# STM32U385 register map
File version: 1.0
CPU: CM33 r0p1, little endian, MPU, FPU, 4 interrupt priority bits
Registers are 32-bit, read-write, reset 0x0 unless marked. A register's access mark holds for its fields unless they carry their own. Offsets are from the block's base; [hi:lo] are bit positions; {n}, {i} and the like mark numbered series.

## DLYBSD1 — DLYB Address block
Base 0x420C8400
Same registers: DLYBOS1 0x420CF000, SEC_DLYBSD1 0x520C8400, SEC_DLYBOS1 0x520CF000
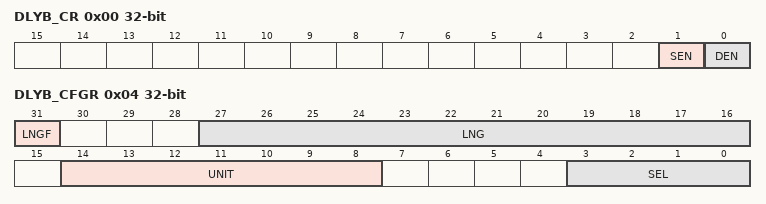
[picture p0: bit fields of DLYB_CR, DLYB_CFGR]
0x00 DLYB_CR — DLYB control register
  [1] SEN — 0: Sampler length and register access to UNIT[6:0] and SEL[3:0] disabled, output clock enabled. 1: Sampler length and register access to UNIT[6:0] and SEL[3:0] enabled, output clock disabled.
    0=Sampler length and register access to UNIT[6:0] and SEL[3:0] disabled, output clock enabled; 1=Sampler length and register access to UNIT[6:0] and SEL[3:0] enabled, output clock disabled
  [0] DEN — 0: DLYB disabled. 1: DLYB enabled.
    0=DLYB disabled; 1=DLYB enabled
0x04 DLYB_CFGR access per field — DLYB configuration register
  [31] LNGF ro — This flag indicates when the delay line length value contained in LNG[11:0] is valid after UNIT[6:0] bits changed. 0: Length value in LNG is not valid. 1: Length value in LNG is valid.
    0=Length value in LNG is not valid; 1=Length value in LNG is valid
  [27:16] LNG ro — These bits reflect the 12 unit delay values sampled at the rising edge of the input clock. The value is only valid when LNGF = 1.
  [14:8] UNIT rw — These bits can only be written when SEN = 1. Unit delay = initial delay + UNIT[6:0] x delay step
  [3:0] SEL rw — These bits can only be written when SEN = 1. Output clock phase = input clock + SEL[3:0] x unit delay

## ExTI — ExTI address block description
Base 0x40032000
Same registers: SEC_ExTI 0x50032000
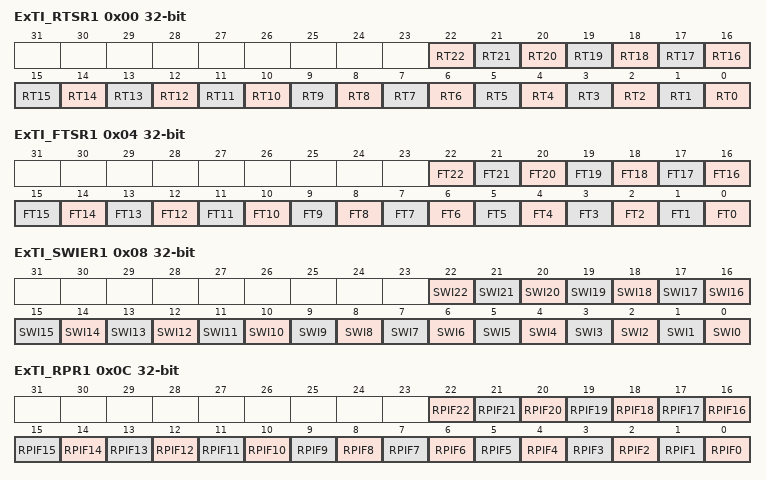
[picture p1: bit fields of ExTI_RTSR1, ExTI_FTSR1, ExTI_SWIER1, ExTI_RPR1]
0x00 ExTI_RTSR1 — ExTI rising trigger selection register
  [all] fields
    0=Rising trigger disabled (for event and interrupt) for input line; 1=Rising trigger enabled (for event and interrupt) for input line
  [n] RT{n} (n=0..22) — Rising trigger event configuration bit of configurable event input i
0x04 ExTI_FTSR1 — ExTI falling trigger selection register
  [all] fields
    0=Falling trigger disabled (for event and interrupt) for input line; 1=Falling trigger enabled (for event and interrupt) for input line
  [n] FT{n} (n=0..22) — Falling trigger event configuration bit of configurable event input i
0x08 ExTI_SWIER1 — ExTI software interrupt event register
  [all] fields
    0=Writing 0 has no effect; 1=Writing 1 triggers a rising edge event on event i
  [n] SWI{n} (n=0..22) — Software interrupt on event i
0x0C ExTI_RPR1 — ExTI rising edge pending register
  [all] fields
    0=No rising edge trigger request occurred; 1=Rising edge trigger request occurred
  [n] RPIF{n} (n=0..22) — Configurable event input i rising edge pending bit
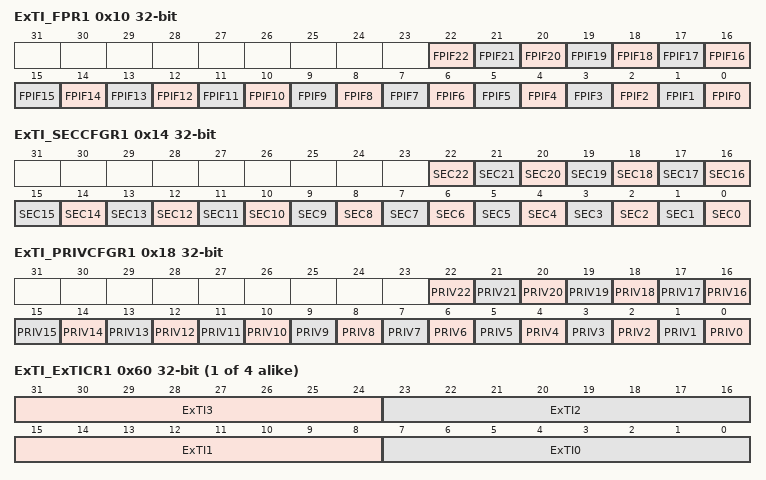
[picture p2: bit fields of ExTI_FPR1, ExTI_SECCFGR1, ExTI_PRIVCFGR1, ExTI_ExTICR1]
0x10 ExTI_FPR1 — ExTI falling edge pending register
  [all] fields
    0=No falling edge trigger request occurred; 1=Falling edge trigger request occurred
  [n] FPIF{n} (n=0..22) — configurable event inputs i falling edge pending bit
0x14 ExTI_SECCFGR1 — ExTI security configuration register
  [all] fields
    0=Event security disabled (nonsecure); 1=Event security enabled (secure)
  [n] SEC{n} (n=0..22) — Security enable on event input i
0x18 ExTI_PRIVCFGR1 — ExTI privilege configuration register
  [all] fields
    0=Event privilege disabled (unprivileged); 1=Event privilege enabled (privileged)
  [n] PRIV{n} (n=0..22) — Security enable on event input i
{0x5C+4i} ExTI_ExTICR{i} (i=1..4) — ExTI external interrupt selection register
  [31:24] ExTI{4i-1} — ExTI{4i-1} GPIO port selection
    0=PA[{4i-1}] pin; 1=PB[{4i-1}] pin; 2=PC[{4i-1}] pin; 3=PD[{4i-1}] pin; 4=PE[{4i-1}] pin; 6=PG[{4i-1}] pin; 7=PH[{4i-1}] pin
  [23:16] ExTI{4i-2} — ExTI{4i-2} GPIO port selection
    0=PA[{4i-2}] pin; 1=PB[{4i-2}] pin; 2=PC[{4i-2}] pin; 3=PD[{4i-2}] pin; 4=PE[{4i-2}] pin; 6=PG[{4i-2}] pin; 7=PH[{4i-2}] pin
  [15:8] ExTI{4i-3}
  [7:0] ExTI{4i-4}
0x70 ExTI_LOCKR — ExTI lock register
  [0] LOCK — Global security and privilege configuration registers (ExTI_SECCFGR and ExTI_PRIVCFGR) lock
    0=Security and privilege configuration open, can be modified; 1=Security and privilege configuration locked, can no longer be modified
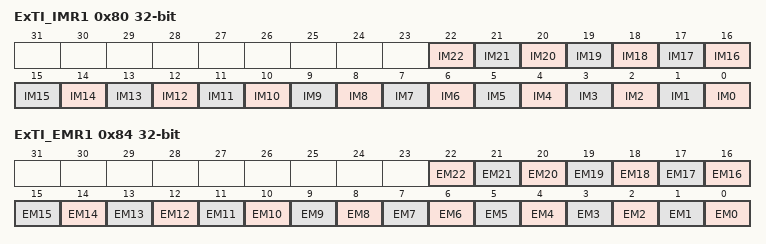
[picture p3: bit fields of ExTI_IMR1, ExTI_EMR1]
0x80 ExTI_IMR1 — ExTI CPU wake-up with interrupt mask register
  [all] fields
    0=Wake-up with interrupt request from input event i is masked; 1=Wake-up with interrupt request from input event i is unmasked
  [n] IM{n} (n=0..22) — CPU wake-up with interrupt mask on event input i
0x84 ExTI_EMR1 — ExTI CPU wake-up with event mask register
  [all] fields
    0=Wake-up with event generation from line i is masked; 1=Wake-up with event generation from line i is unmasked
  [n] EM{n} (n=0..22) — CPU wake-up with event generation mask on event input i
